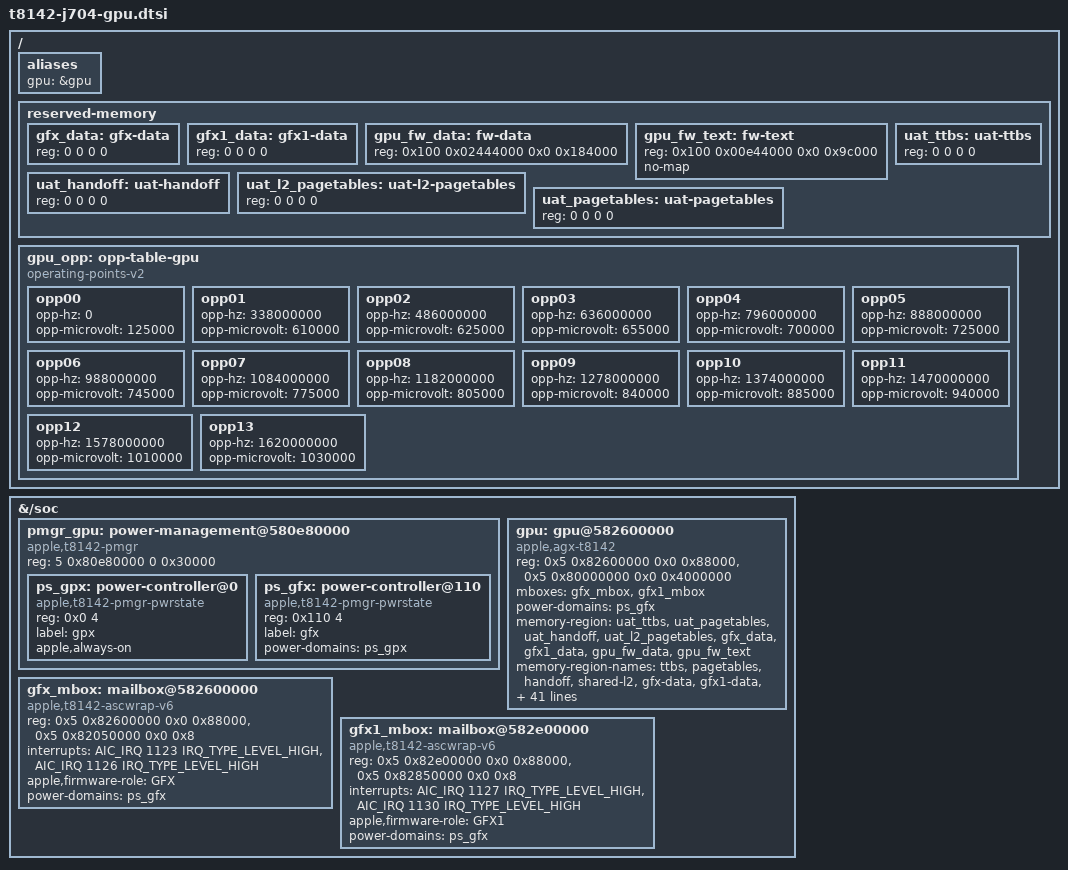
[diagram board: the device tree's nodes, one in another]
// SPDX-License-Identifier: GPL-2.0+ OR MIT
/*
 * M5 (T8142) GPU of the J704 (MacBook Pro 14-inch, M5): t8142-j813-gpu.dtsi with
 * fourteen OPPs. Every address, interrupt and power domain was checked against the
 * J704 ADT and is the same as on the J813:
 *   sgx       reg 0x580000000+0x4000000 (and 0x580d00000+0x180000, unused here)
 *   gfx-asc   reg 0x582600000+0x88000, iop-vbar 0x582050000+0x8,
 *             interrupts [1124, 1123, 1126, 1125], role GFX
 *   gfx1-asc  reg 0x582e00000+0x88000, iop-vbar 0x582850000+0x8,
 *             interrupts [1128, 1127, 1130, 1129], role GFX1
 *   pmgr      GPU block 0x580e80000: gpx at +0, gfx at +0x110 (sgx clock-gates 515/516,
 *             gfx-asc 517, gfx1-asc 518)
 *   sgx gfx-data 0x10002444000+0xc0000, gfx-data-shared-ro 0x10002504000+0x8000,
 *       gfx1-data 0x1000250c000+0xb4000, gfx1-data-shared-ro 0x100025c0000+0x8000:
 *       the fixed fw-data span below (0x10002444000+0x184000) is exactly the J704's.
 * The ADT has perf-state-count 14 (gpu-num-perf-states 13, one table): the bootloader
 * (aura kboot_gpu.c dt_set_gpu_g17, which accepts 14/13 as T8142's alternative count)
 * requires exactly that many OPP nodes, each with a u64 opp-hz and one u32
 * opp-microvolt, and fills them from sgx perf-states; it fills the uat-* regions from
 * iBoot's raw-boot handoff and gfx-data/gfx1-data/fw-data from the firmware segments.
 * The OPP values below are the J704 ADT's (the loader overwrites them with the same).
 */

/ {
	aliases {
		gpu = &gpu;
	};

	reserved-memory {
		/* gfx-asc and gfx1-asc __DATA (ADT sgx gfx-data, gfx1-data) */
		gfx_data: gfx-data {
			reg = <0 0 0 0>;
		};

		gfx1_data: gfx1-data {
			reg = <0 0 0 0>;
		};

		/*
		 * macOS 27.0 (26A428): both roles' __DATA and __DATA_SHARED_RO, contiguous
		 * (ADT gfx-asc and gfx1-asc segment-ranges), where the firmware places its crash
		 * logs. Fixed at the addresses iBoot has used on every 27.0 boot so far, until the
		 * bootloader fills it in.
		 */
		/* Mapped like gfx-data: the driver reads the crash logs through the linear map. */
		gpu_fw_data: fw-data {
			reg = <0x100 0x02444000 0x0 0x184000>;
		};

		/*
		 * Both roles' __TEXT, contiguous (J704 ADT gfx-asc 0x100_00e4_4000 + 0x50000 and
		 * gfx1-asc 0x100_00e9_4000 + 0x4c000, as on the J813), which the driver identifies
		 * before it starts the firmware. Fixed at the macOS 27.0 address like fw-data, until
		 * the bootloader fills it in.
		 */
		gpu_fw_text: fw-text {
			reg = <0x100 0x00e44000 0x0 0x9c000>;
			no-map;
		};

		uat_handoff: uat-handoff {
			reg = <0 0 0 0>;
		};

		uat_l2_pagetables: uat-l2-pagetables {
			reg = <0 0 0 0>;
		};

		uat_pagetables: uat-pagetables {
			reg = <0 0 0 0>;
		};

		uat_ttbs: uat-ttbs {
			reg = <0 0 0 0>;
		};
	};

	gpu_opp: opp-table-gpu {
		compatible = "operating-points-v2";

		/*
		 * 14 entries in perf-state order (ADT sgx perf-states: MHz, core mV),
		 * refilled by the bootloader.
		 */
		opp00 { opp-hz = /bits/ 64 <0>; opp-microvolt = <125000>; };
		opp01 { opp-hz = /bits/ 64 <338000000>; opp-microvolt = <610000>; };
		opp02 { opp-hz = /bits/ 64 <486000000>; opp-microvolt = <625000>; };
		opp03 { opp-hz = /bits/ 64 <636000000>; opp-microvolt = <655000>; };
		opp04 { opp-hz = /bits/ 64 <796000000>; opp-microvolt = <700000>; };
		opp05 { opp-hz = /bits/ 64 <888000000>; opp-microvolt = <725000>; };
		opp06 { opp-hz = /bits/ 64 <988000000>; opp-microvolt = <745000>; };
		opp07 { opp-hz = /bits/ 64 <1084000000>; opp-microvolt = <775000>; };
		opp08 { opp-hz = /bits/ 64 <1182000000>; opp-microvolt = <805000>; };
		opp09 { opp-hz = /bits/ 64 <1278000000>; opp-microvolt = <840000>; };
		opp10 { opp-hz = /bits/ 64 <1374000000>; opp-microvolt = <885000>; };
		opp11 { opp-hz = /bits/ 64 <1470000000>; opp-microvolt = <940000>; };
		opp12 { opp-hz = /bits/ 64 <1578000000>; opp-microvolt = <1010000>; };
		opp13 { opp-hz = /bits/ 64 <1620000000>; opp-microvolt = <1030000>; };
	};
};

&{/soc} {
	pmgr_gpu: power-management@580e80000 {
		compatible = "apple,t8142-pmgr", "apple,t8103-pmgr", "syscon", "simple-mfd";
		reg = <5 0x80e80000 0 0x30000>;
		#address-cells = <1>;
		#size-cells = <1>;

		ps_gpx: power-controller@0 {
			compatible = "apple,t8142-pmgr-pwrstate", "apple,t8103-pmgr-pwrstate";
			reg = <0x0 4>;
			#power-domain-cells = <0>;
			#reset-cells = <0>;
			label = "gpx";
			apple,always-on; /* critical */
		};

		ps_gfx: power-controller@110 {
			compatible = "apple,t8142-pmgr-pwrstate", "apple,t8103-pmgr-pwrstate";
			reg = <0x110 4>;
			#power-domain-cells = <0>;
			#reset-cells = <0>;
			label = "gfx";
			power-domains = <&ps_gpx>;
		};
	};

	gpu: gpu@582600000 {
		compatible = "apple,agx-t8142";
		reg = <0x5 0x82600000 0x0 0x88000>,
		      <0x5 0x80000000 0x0 0x4000000>;
		reg-names = "asc", "sgx";
		mboxes = <&gfx_mbox>, <&gfx1_mbox>;
		power-domains = <&ps_gfx>;
		memory-region = <&uat_ttbs>, <&uat_pagetables>, <&uat_handoff>,
				<&uat_l2_pagetables>, <&gfx_data>, <&gfx1_data>,
				<&gpu_fw_data>, <&gpu_fw_text>;
		memory-region-names = "ttbs", "pagetables", "handoff",
				      "shared-l2", "gfx-data", "gfx1-data", "fw-data",
				      "fw-text";
		operating-points-v2 = <&gpu_opp>;
		/* Holds the DCS and fabric floor while GPU work is in flight. */
		apple,clpc = <&clpc>;

		/*
		 * The J704's GPU power data, which the driver requires: the J704 ADT's (sgx)
		 * or macOS 27.0's own InitData on a J704 (26A428, every startup capture alike).
		 * SRAM voltage per OPP: the ADT's sgx perf-states-sram, which macOS also has at
		 * hardware data +0x1524.
		 */
		apple,sram-microvolt = <770000 770000 770000 770000 770000 770000 770000
					775000 805000 840000 885000 940000 1010000 1030000>;
		/*
		 * Relative performance per OPP (IEEE single, percent), hardware data +0x19e4:
		 * 0, 11.52, 15.13, 20.03, 27.18, 31.89, 36.86, 43.31, 50.58, 59.33, 71.35,
		 * 87.47, 98.06, 100.
		 */
		apple,m5-relative-power = <0 0x413859bf 0x41721ec4 0x41a0407d 0x41d969aa
					   0x41ff2298 0x42137266 0x422d41a1 0x424a5481
					   0x426d5023 0x428eb134 0x42aeee33 0x42c41dd3
					   0x42c80000>;
		/*
		 * The AON rows as macOS 27.0 hands them over: RT0g first (index 0x28, the row
		 * the power policy names), then LFCR, LFXG and PLXG.
		 */
		apple,m5-aon-records = <0x67305452 0x00280001 0x00001401>,
				       <0x5243464c 0x00b10001 0x0000ff01>,
				       <0x4758464c 0x014f0001 0x0000ff01>,
				       <0x47584c50 0x014e0001 0x0000ff01>;
		/*
		 * The J813's words, except that +0x1118 is not cleared: it is state 13's
		 * frequency, 1620 MHz here.
		 */
		apple,m5-hw-words = <0x0fa8 0x8000>, <0x0fb4 2>, <0x0fb8 0>, <0x1044 0xc>,
				    <0x10a4 0xa>, <0x10d4 0x17>, <0x2660 4>, <0x2720 1>,
				    <0x2724 0>;
		/*
		 * Region C where it differs from the driver's template: the power words at
		 * +0x88 (0x94de) and +0x8c, +0x90, +0x9c (0x514); +0x9b0 is 0.
		 */
		apple,m5-region-c-words = <0x088 0x94de>, <0x08c 0x514>, <0x090 0x514>,
					  <0x09c 0x514>, <0x9b0 0>;
		/*
		 * The power policy block (26A428 offsets) where it differs from the driver's
		 * template: the higher power limits (1300, 0x94de = 38110 and the floats derived
		 * from them), the top frequency at +0x22b4 (1620 MHz) and at +0x6560.. the
		 * policy's references to the AON rows after RT0g.
		 */
		apple,m5-policy-words = <0x0048 0x514>, <0x0088 0x514>, <0x09f0 0x4714de00>,
					<0x09fc 0xbd0bb8cc>, <0x0a04 0x514>, <0x0a08 0x514>,
					<0x0a14 0x94de>, <0x0a48 0x514>, <0x0abc 0x514>,
					<0x0acc 0x94de>, <0x0b38 0x4b>, <0x0b84 0x414a1af3>,
					<0x0b8c 0x514>, <0x0ca0 0x0>, <0x22ac 0x42c80000>,
					<0x22b0 0x44a28000>, <0x22b4 0x654>, <0x22c8 0x64>,
					<0x22d4 0x514>, <0x236c 0x514>, <0x2370 0x514>,
					<0x23b0 0x514>, <0x2810 0x5140000>, <0x2854 0x5140000>,
					<0x2928 0x514>, <0x2988 0x10001>, <0x2a88 0x0>,
					<0x2aa0 0x94de>, <0x2aa4 0x94de>, <0x2aa8 0x94de>,
					<0x2bd0 0x514>, <0x2bd4 0x514>, <0x2bdc 0x4714de00>,
					<0x2be0 0x94de>, <0x2c14 0x514>, <0x2d60 0x514>,
					<0x2e1c 0x514>, <0x2fb4 0x514>, <0x2fb8 0x514>,
					<0x301c 0x4b0>, <0x3020 0x514>, <0x3024 0x514>,
					<0x3030 0x514>, <0x3064 0x514>, <0x30ac 0x0>,
					<0x6560 0x5243464c>, <0x6564 0x4758464c>, <0x6568 0x3>,
					<0x6570 0x47584c50>, <0x6574 0x1>, <0x6580 0x1>,
					<0x6c6c 0x42e06667>, <0x6cac 0x44b30000>,
					<0x6cec 0x42ca0000>;
		apple,idleoff-standby-timer = <2000>;
	};

	gfx_mbox: mailbox@582600000 {
		compatible = "apple,t8142-ascwrap-v6";
		reg = <0x5 0x82600000 0x0 0x88000>,
		      <0x5 0x82050000 0x0 0x8>;
		reg-names = "wrapper", "iop-vbar";
		interrupts = <AIC_IRQ 1123 IRQ_TYPE_LEVEL_HIGH>,
			     <AIC_IRQ 1126 IRQ_TYPE_LEVEL_HIGH>;
		interrupt-names = "send-empty", "recv-not-empty";
		apple,firmware-role = "GFX";
		power-domains = <&ps_gfx>;
		#mbox-cells = <0>;
	};

	gfx1_mbox: mailbox@582e00000 {
		compatible = "apple,t8142-ascwrap-v6";
		reg = <0x5 0x82e00000 0x0 0x88000>,
		      <0x5 0x82850000 0x0 0x8>;
		reg-names = "wrapper", "iop-vbar";
		interrupts = <AIC_IRQ 1127 IRQ_TYPE_LEVEL_HIGH>,
			     <AIC_IRQ 1130 IRQ_TYPE_LEVEL_HIGH>;
		interrupt-names = "send-empty", "recv-not-empty";
		apple,firmware-role = "GFX1";
		power-domains = <&ps_gfx>;
		#mbox-cells = <0>;
	};
};
